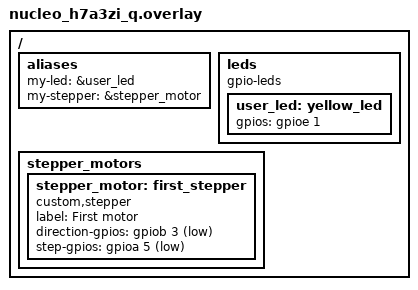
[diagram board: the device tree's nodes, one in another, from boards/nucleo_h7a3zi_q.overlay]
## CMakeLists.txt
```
cmake_minimum_required(VERSION 3.20)
find_package(Zephyr REQUIRED HINTS $ENV{ZEPHYR_BASE})
project(rmrc)
target_sources(app PRIVATE src/main.c src/motor.c)
target_include_directories(app PUBLIC ${CMAKE_CURRENT_SOURCE_DIR}/lib)
```

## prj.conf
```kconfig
CONFIG_GPIO=y
CONFIG_CONSOLE_SUBSYS=y
CONFIG_CONSOLE_GETLINE=y
CONFIG_UART_LINE_CTRL=y
CONFIG_UART_INTERRUPT_DRIVEN=y
CONFIG_PRINTK=y
CONFIG_SERIAL=y
CONFIG_CONSOLE=y
CONFIG_UART_CONSOLE=y
```

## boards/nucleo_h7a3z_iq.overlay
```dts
/{
   aliases {
     my-led=&yellow_led;
   };
   leds : leds {
  	compatible="gpio-leds";
  	yellow_led: e1 {
  	  gpios=<&gpioe 1 GPIO_ACTIVE-HIGH>;
	};

   };


};
```

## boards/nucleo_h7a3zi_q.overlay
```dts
/ {
    aliases {
        my-led = &user_led;
        my-stepper = &stepper_motor;
    };

    leds {
        compatible = "gpio-leds";

        user_led: yellow_led {
           gpios = <&gpioe 1 GPIO_ACTIVE_HIGH>;
        };
    };
    stepper_motors {

        stepper_motor: first_stepper {
           compatible="custom,stepper";
           label="First motor";
           direction-gpios = <&gpiob 3 GPIO_ACTIVE_LOW>;
           step-gpios = <&gpioa 5 GPIO_ACTIVE_LOW>;
        };
      
    };

};
```

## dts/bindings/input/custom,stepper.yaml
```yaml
description : Custom stepper
compatible : "custom,stepper"
properties :
  label :
    type : string
    required : false
  direction-gpios :
    type : phandle-array
    required : true
  step-gpios :
    type : phandle-array
    required : true
```

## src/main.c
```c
#include <stdio.h>
#include <zephyr/sys/printk.h>
#include <zephyr/kernel.h>
#include <zephyr/drivers/gpio.h>
#include <zephyr/console/console.h>
#include "motor.h"
#define sleep_time_ms 3
#define CONTROL_STACK_SIZE 512
#define MOTOR_STACK_SIZE 512
char msgq_buffer[10*sizeof(uint8_t)];
static struct k_msgq my_msgq;

K_THREAD_STACK_DEFINE(control_stack,CONTROL_STACK_SIZE);
K_THREAD_STACK_DEFINE(motor_stack,MOTOR_STACK_SIZE);
static struct  k_thread control_thread;
static struct k_thread motor_thred;
//K_MUTEX_DEFINE(stepper_mutex);
uint8_t rotation;
static const struct gpio_dt_spec led=GPIO_DT_SPEC_GET(DT_ALIAS(my_led),gpios);
static const struct gpio_dt_spec dir_motor=GPIO_DT_SPEC_GET(DT_ALIAS(my_stepper),direction_gpios);
static const struct gpio_dt_spec step_motor=GPIO_DT_SPEC_GET(DT_ALIAS(my_stepper),step_gpios);
static const struct stepper_motor my_motor = {
  .direction=dir_motor,
  .step=step_motor
};
void control_thread_start(void *arg1,void *arg2 , void *arg3){
  uint8_t dir;
  while(1){
    char *line=console_getline();
    if(line[0]=='w'){
      dir=1;
    }else if(line[0]=='a'){
      dir=0;
    }else {
      continue;
    }
    k_msgq_put(&my_msgq,&dir,K_NO_WAIT);
    /*
    k_mutex_lock(&stepper_mutex,K_FOREVER);
    rotation=(uint8_t)dir;
    k_mutex_unlock(&stepper_mutex);
    printk("Direction of rotation is : %d\n",rotation);
    */
    k_msleep(10);
  }
}

void motor_thread_start(void *arg1 , void *arg2 , void *arg3){
  uint8_t pulse=0;
  uint8_t direction_rotation=0;
  while(1){
    /*
    k_mutex_lock(&stepper_mutex,K_FOREVER);
    direction_rotation=rotation;
    k_mutex_unlock(&stepper_mutex);
    */
    k_msgq_get(&my_msgq,&direction_rotation,K_FOREVER);
    printk("The direction of the motor is : %d\n",direction_rotation);
    for(int i=0;i<50;i++){
      pulse=step_motion(&my_motor,direction_rotation,pulse);
    };
    if((pulse & 0x03)==0){
      gpio_pin_set_dt(&led,1);
      k_msleep(3);
    }else {
      gpio_pin_set_dt(&led,0);
    }
    printk("Rotating the stepper motor to one step \n");
  }
}
int main() {
  int motor_dir;
  int motor_step;
  uint8_t status=0;
  int ret;
  console_getline_init();
  status=1;
  ret=gpio_pin_configure_dt(&led,GPIO_OUTPUT_ACTIVE);
  motor_dir=gpio_pin_configure_dt(&dir_motor,GPIO_OUTPUT_ACTIVE);
  motor_step=gpio_pin_configure_dt(&step_motor,GPIO_OUTPUT_ACTIVE);
  k_tid_t motor;
  k_tid_t control;
  k_msgq_init(&my_msgq,msgq_buffer,sizeof(uint8_t),10);
  motor=k_thread_create(&motor_thred,motor_stack,K_THREAD_STACK_SIZEOF(motor_stack),motor_thread_start,NULL,NULL,NULL,8,0,K_NO_WAIT);
  control=k_thread_create(&control_thread,control_stack,K_THREAD_STACK_SIZEOF(control_stack),control_thread_start,NULL,NULL,NULL,7,0,K_NO_WAIT);
  gpio_pin_set_dt(&led,1);
  gpio_pin_set_dt(&dir_motor,0);
  gpio_pin_set_dt(&step_motor,0);
  if(motor_dir <0){
    printk("Device stepper nto configured properly");
  }
  if (motor_step <0){
    printk("Device stepper not configured properly the pulse channel");
  }
  if(ret<0){
    printk("Device led not configured proeprly");
  }
  while(1){
    /*
    char *line=console_getline();
    printk("Enter the direction to move\n");
    scanf(" %c",&input);
    if(input=='w'){
      dir=1;
    }else if(input =='a'){
      dir=0;
    }else {
      printk("Invalid key presses \n");
      return 0;
    }
    */
    /*
    if(line[0]=='w'){
      dir=1;
    }else if(line[0]=='a'){
      dir=0;
    }else {
      printk("Invalid character \n");
      continue;
    }
    pos=step_motion(&my_motor,dir,pos);
    if((pos & 0x03) ==0){
      gpio_pin_set_dt(&led,1);
      printk("led is ON stepper moved one step forward or back");
    }else{
      gpio_pin_set_dt(&led,0);
      printk("led is OFF");
    }
    */
    /*
    if(status==1){
      status=0;
    }else if(status==0){
      status=1;
    }
    
    printk("Status of the led : %d\n",status);
    gpio_pin_set_dt(&led,status);
    */
    k_sleep(K_FOREVER);
  }



}
```

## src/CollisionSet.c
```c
/*
 * Sponsored License - for use in support of a program or activity
 * sponsored by MathWorks.  Not for government, commercial or other
 * non-sponsored organizational use.
 * File: CollisionSet.c
 *
 * MATLAB Coder version            : 25.2
 * C/C++ source code generated on  : 07-Mar-2026 20:10:01
 */

/* Include Files */
#include "CollisionSet.h"
#include "psudoinverse_function_data.h"
#include "psudoinverse_function_emxutil.h"
#include "psudoinverse_function_types.h"
#include "rt_nonfinite.h"

/* Function Definitions */
/*
 * Arguments    : d_robotics_manip_internal_Colli *obj
 *                double maxElements
 * Return Type  : d_robotics_manip_internal_Colli *
 */
d_robotics_manip_internal_Colli *
CollisionSet_CollisionSet(d_robotics_manip_internal_Colli *obj,
                          double maxElements)
{
  static const void *t0_GeometryInternal = NULL;
  c_robotics_manip_internal_Colli expl_temp;
  d_robotics_manip_internal_Colli *b_obj;
  double d;
  int b_i;
  int i;
  int i1;
  int size_tmp_idx_1;
  b_obj = obj;
  b_obj->Size = 0.0;
  b_obj->MaxElements = maxElements;
  size_tmp_idx_1 = (int)b_obj->MaxElements;
  i = b_obj->CollisionGeometries->size[0] * b_obj->CollisionGeometries->size[1];
  b_obj->CollisionGeometries->size[0] = 1;
  b_obj->CollisionGeometries->size[1] = size_tmp_idx_1;
  c_emxEnsureCapacity_robotics_ma(b_obj->CollisionGeometries, i);
  d = b_obj->MaxElements;
  size_tmp_idx_1 = (int)d;
  for (b_i = 0; b_i < size_tmp_idx_1; b_i++) {
    expl_temp.CollisionPrimitive = (void *)t0_GeometryInternal;
    for (i1 = 0; i1 < 16; i1++) {
      expl_temp.LocalPose[i1] = iv[i1];
    }
    for (i1 = 0; i1 < 16; i1++) {
      expl_temp.WorldPose[i1] = iv[i1];
    }
    expl_temp.MeshScale[0] = 1.0;
    expl_temp.MeshScale[1] = 1.0;
    expl_temp.MeshScale[2] = 1.0;
    expl_temp.ColorAlpha[0] = 0.46666666666666667;
    expl_temp.ColorAlpha[1] = 0.67450980392156867;
    expl_temp.ColorAlpha[2] = 0.18823529411764706;
    expl_temp.ColorAlpha[3] = 1.0;
    b_obj->CollisionGeometries->data[b_i] = expl_temp;
  }
  b_obj->matlabCodegenIsDeleted = false;
  return b_obj;
}

/*
 * File trailer for CollisionSet.c
 *
 * [EOF]
 */
```

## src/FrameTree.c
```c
/*
 * Sponsored License - for use in support of a program or activity
 * sponsored by MathWorks.  Not for government, commercial or other
 * non-sponsored organizational use.
 * File: FrameTree.c
 *
 * MATLAB Coder version            : 25.2
 * C/C++ source code generated on  : 07-Mar-2026 20:10:01
 */

/* Include Files */
#include "FrameTree.h"
#include "psudoinverse_function_data.h"
#include "psudoinverse_function_types.h"
#include "rt_nonfinite.h"
#include <string.h>

/* Function Definitions */
/*
 * Arguments    : const emxArray_uint8_T *obj_FrameNames
 *                double obj_NumFrames
 * Return Type  : double
 */
double FrameTree_getFrameIdx(const emxArray_uint8_T *obj_FrameNames,
                             double obj_NumFrames)
{
  double fidx;
  int b_i;
  int i;
  unsigned char u8Name[200];
  const unsigned char *obj_FrameNames_data;
  bool exitg1;
  obj_FrameNames_data = obj_FrameNames->data;
  fidx = -1.0;
  memset(&u8Name[0], 0, 200U * sizeof(unsigned char));
  for (i = 0; i < 9; i++) {
    u8Name[i] = uv[i];
  }
  b_i = 0;
  exitg1 = false;
  while ((!exitg1) && (b_i <= (int)obj_NumFrames - 1)) {
    int k;
    bool x[200];
    bool exitg2;
    bool y;
    for (i = 0; i < 200; i++) {
      x[i] =
          (obj_FrameNames_data[b_i + obj_FrameNames->size[0] * i] == u8Name[i]);
    }
    y = true;
    k = 0;
    exitg2 = false;
    while ((!exitg2) && (k < 200)) {
      if (!x[k]) {
        y = false;
        exitg2 = true;
      } else {
        k++;
      }
    }
    if (y) {
      fidx = (double)b_i + 1.0;
      exitg1 = true;
    } else {
      b_i++;
    }
  }
  return fidx;
}

/*
 * Arguments    : const emxArray_uint8_T *obj_FrameNames
 *                double obj_NumFrames
 *                double *fidx
 * Return Type  : bool
 */
bool FrameTree_isFrameInTree(const emxArray_uint8_T *obj_FrameNames,
                             double obj_NumFrames, double *fidx)
{
  static const unsigned char b_uv[6] = {108U, 105U, 110U, 107U, 95U, 49U};
  int b_i;
  int i;
  unsigned char u8Name[200];
  const unsigned char *obj_FrameNames_data;
  bool exitg1;
  bool tf;
  obj_FrameNames_data = obj_FrameNames->data;
  *fidx = -1.0;
  memset(&u8Name[0], 0, 200U * sizeof(unsigned char));
  for (i = 0; i < 6; i++) {
    u8Name[i] = b_uv[i];
  }
  b_i = 0;
  exitg1 = false;
  while ((!exitg1) && (b_i <= (int)obj_NumFrames - 1)) {
    int k;
    bool x[200];
    bool exitg2;
    for (i = 0; i < 200; i++) {
      x[i] =
          (obj_FrameNames_data[b_i + obj_FrameNames->size[0] * i] == u8Name[i]);
    }
    tf = true;
    k = 0;
    exitg2 = false;
    while ((!exitg2) && (k < 200)) {
      if (!x[k]) {
        tf = false;
        exitg2 = true;
      } else {
        k++;
      }
    }
    if (tf) {
      *fidx = (double)b_i + 1.0;
      exitg1 = true;
    } else {
      b_i++;
    }
  }
  return *fidx > 0.0;
}

/*
 * Arguments    : const emxArray_real_T *obj_FrameParents
 *                const emxArray_real_T *obj_FrameRigidTransforms
 *                double fid1
 *                double tform[16]
 * Return Type  : void
 */
void FrameTree_transformUsingFrameID(
    const emxArray_real_T *obj_FrameParents,
    const emxArray_real_T *obj_FrameRigidTransforms, double fid1,
    double tform[16])
{
  double T1[16];
  double b_R[16];
  double d_R[3];
  const double *obj_FrameParents_data;
  const double *obj_FrameRigidTransforms_data;
  int i;
  int i1;
  obj_FrameRigidTransforms_data = obj_FrameRigidTransforms->data;
  obj_FrameParents_data = obj_FrameParents->data;
  if (fid1 == 1.0) {
    memset(&tform[0], 0, 16U * sizeof(double));
    tform[0] = 1.0;
    tform[5] = 1.0;
    tform[10] = 1.0;
    tform[15] = 1.0;
  } else {
    double R[9];
    double c_R[9];
    double d;
    double d1;
    double fid;
    int T1_tmp;
    int b_T1_tmp;
    fid = fid1;
    for (i = 0; i < 4; i++) {
      T1_tmp = i << 2;
      b_T1_tmp = 4 * i + 16 * ((int)fid1 - 1);
      T1[T1_tmp] = obj_FrameRigidTransforms_data[b_T1_tmp];
      T1[T1_tmp + 1] = obj_FrameRigidTransforms_data[b_T1_tmp + 1];
      T1[T1_tmp + 2] = obj_FrameRigidTransforms_data[b_T1_tmp + 2];
      T1[T1_tmp + 3] = obj_FrameRigidTransforms_data[b_T1_tmp + 3];
    }
    while (fid > 1.0) {
      memset(&b_R[0], 0, sizeof(double) << 4);
      for (i = 0; i < 4; i++) {
        b_T1_tmp = i << 2;
        for (i1 = 0; i1 < 4; i1++) {
          d = T1[i1 + b_T1_tmp];
          T1_tmp = (int)obj_FrameParents_data[(int)fid - 1] - 1;
          T1_tmp = 4 * i1 + 16 * T1_tmp;
          b_R[b_T1_tmp] += obj_FrameRigidTransforms_data[T1_tmp] * d;
          b_R[b_T1_tmp + 1] += obj_FrameRigidTransforms_data[T1_tmp + 1] * d;
          b_R[b_T1_tmp + 2] += obj_FrameRigidTransforms_data[T1_tmp + 2] * d;
          b_R[b_T1_tmp + 3] += obj_FrameRigidTransforms_data[T1_tmp + 3] * d;
        }
      }
      memcpy(&T1[0], &b_R[0], 16U * sizeof(double));
      fid = obj_FrameParents_data[(int)fid - 1];
    }
    for (i = 0; i < 3; i++) {
      R[3 * i] = obj_FrameRigidTransforms_data[i];
      R[3 * i + 1] = obj_FrameRigidTransforms_data[i + 4];
      R[3 * i + 2] = obj_FrameRigidTransforms_data[i + 8];
    }
    for (i = 0; i < 9; i++) {
      c_R[i] = -R[i];
    }
    memset(&d_R[0], 0, 3U * sizeof(double));
    fid = d_R[0];
    d = d_R[1];
    d1 = d_R[2];
    for (i = 0; i < 3; i++) {
      double d2;
      d2 = obj_FrameRigidTransforms_data[i + 12];
      fid += c_R[3 * i] * d2;
      b_T1_tmp = i << 2;
      b_R[b_T1_tmp] = R[3 * i];
      T1_tmp = 3 * i + 1;
      d += c_R[T1_tmp] * d2;
      b_R[b_T1_tmp + 1] = R[T1_tmp];
      T1_tmp = 3 * i + 2;
      d1 += c_R[T1_tmp] * d2;
      b_R[b_T1_tmp + 2] = R[T1_tmp];
    }
    b_R[12] = fid;
    b_R[13] = d;
    b_R[14] = d1;
    b_R[3] = 0.0;
    b_R[7] = 0.0;
    b_R[11] = 0.0;
    b_R[15] = 1.0;
    memset(&tform[0], 0, sizeof(double) << 4);
    for (i = 0; i < 4; i++) {
      T1_tmp = i << 2;
      for (i1 = 0; i1 < 4; i1++) {
        fid = T1[i1 + T1_tmp];
        b_T1_tmp = i1 << 2;
        tform[T1_tmp] += b_R[b_T1_tmp] * fid;
        tform[T1_tmp + 1] += b_R[b_T1_tmp + 1] * fid;
        tform[T1_tmp + 2] += b_R[b_T1_tmp + 2] * fid;
        tform[T1_tmp + 3] += b_R[b_T1_tmp + 3] * fid;
      }
    }
  }
}

/*
 * Arguments    : const emxArray_uint8_T *obj_FrameNames
 *                double obj_NumFrames
 *                double *fidx
 * Return Type  : bool
 */
bool b_FrameTree_isFrameInTree(const emxArray_uint8_T *obj_FrameNames,
                               double obj_NumFrames, double *fidx)
{
  static const unsigned char b_uv[6] = {108U, 105U, 110U, 107U, 95U, 50U};
  int b_i;
  int i;
  unsigned char u8Name[200];
  const unsigned char *obj_FrameNames_data;
  bool exitg1;
  bool tf;
  obj_FrameNames_data = obj_FrameNames->data;
  *fidx = -1.0;
  memset(&u8Name[0], 0, 200U * sizeof(unsigned char));
  for (i = 0; i < 6; i++) {
    u8Name[i] = b_uv[i];
  }
  b_i = 0;
  exitg1 = false;
  while ((!exitg1) && (b_i <= (int)obj_NumFrames - 1)) {
    int k;
    bool x[200];
    bool exitg2;
    for (i = 0; i < 200; i++) {
      x[i] =
          (obj_FrameNames_data[b_i + obj_FrameNames->size[0] * i] == u8Name[i]);
    }
    tf = true;
    k = 0;
    exitg2 = false;
    while ((!exitg2) && (k < 200)) {
      if (!x[k]) {
        tf = false;
        exitg2 = true;
      } else {
        k++;
      }
    }
    if (tf) {
      *fidx = (double)b_i + 1.0;
      exitg1 = true;
    } else {
      b_i++;
    }
  }
  return *fidx > 0.0;
}

/*
 * Arguments    : const emxArray_uint8_T *obj_FrameNames
 *                double obj_NumFrames
 *                double *fidx
 * Return Type  : bool
 */
bool c_FrameTree_isFrameInTree(const emxArray_uint8_T *obj_FrameNames,
                               double obj_NumFrames, double *fidx)
{
  static const unsigned char b_uv[6] = {108U, 105U, 110U, 107U, 95U, 51U};
  int b_i;
  int i;
  unsigned char u8Name[200];
  const unsigned char *obj_FrameNames_data;
  bool exitg1;
  bool tf;
  obj_FrameNames_data = obj_FrameNames->data;
  *fidx = -1.0;
  memset(&u8Name[0], 0, 200U * sizeof(unsigned char));
  for (i = 0; i < 6; i++) {
    u8Name[i] = b_uv[i];
  }
  b_i = 0;
  exitg1 = false;
  while ((!exitg1) && (b_i <= (int)obj_NumFrames - 1)) {
    int k;
    bool x[200];
    bool exitg2;
    for (i = 0; i < 200; i++) {
      x[i] =
          (obj_FrameNames_data[b_i + obj_FrameNames->size[0] * i] == u8Name[i]);
    }
    tf = true;
    k = 0;
    exitg2 = false;
    while ((!exitg2) && (k < 200)) {
      if (!x[k]) {
        tf = false;
        exitg2 = true;
      } else {
        k++;
      }
    }
    if (tf) {
      *fidx = (double)b_i + 1.0;
      exitg1 = true;
    } else {
      b_i++;
    }
  }
  return *fidx > 0.0;
}

/*
 * Arguments    : const emxArray_uint8_T *obj_FrameNames
 *                double obj_NumFrames
 *                double *fidx
 * Return Type  : bool
 */
bool d_FrameTree_isFrameInTree(const emxArray_uint8_T *obj_FrameNames,
                               double obj_NumFrames, double *fidx)
{
  static const unsigned char b_uv[6] = {108U, 105U, 110U, 107U, 95U, 52U};
  int b_i;
  int i;
  unsigned char u8Name[200];
  const unsigned char *obj_FrameNames_data;
  bool exitg1;
  bool tf;
  obj_FrameNames_data = obj_FrameNames->data;
  *fidx = -1.0;
  memset(&u8Name[0], 0, 200U * sizeof(unsigned char));
  for (i = 0; i < 6; i++) {
    u8Name[i] = b_uv[i];
  }
  b_i = 0;
  exitg1 = false;
  while ((!exitg1) && (b_i <= (int)obj_NumFrames - 1)) {
    int k;
    bool x[200];
    bool exitg2;
    for (i = 0; i < 200; i++) {
      x[i] =
          (obj_FrameNames_data[b_i + obj_FrameNames->size[0] * i] == u8Name[i]);
    }
    tf = true;
    k = 0;
    exitg2 = false;
    while ((!exitg2) && (k < 200)) {
      if (!x[k]) {
        tf = false;
        exitg2 = true;
      } else {
        k++;
      }
    }
    if (tf) {
      *fidx = (double)b_i + 1.0;
      exitg1 = true;
    } else {
      b_i++;
    }
  }
  return *fidx > 0.0;
}

/*
 * Arguments    : const emxArray_uint8_T *obj_FrameNames
 *                double obj_NumFrames
 *                double *fidx
 * Return Type  : bool
 */
bool e_FrameTree_isFrameInTree(const emxArray_uint8_T *obj_FrameNames,
                               double obj_NumFrames, double *fidx)
{
  static const unsigned char b_uv[6] = {108U, 105U, 110U, 107U, 95U, 53U};
  int b_i;
  int i;
  unsigned char u8Name[200];
  const unsigned char *obj_FrameNames_data;
  bool exitg1;
  bool tf;
  obj_FrameNames_data = obj_FrameNames->data;
  *fidx = -1.0;
  memset(&u8Name[0], 0, 200U * sizeof(unsigned char));
  for (i = 0; i < 6; i++) {
    u8Name[i] = b_uv[i];
  }
  b_i = 0;
  exitg1 = false;
  while ((!exitg1) && (b_i <= (int)obj_NumFrames - 1)) {
    int k;
    bool x[200];
    bool exitg2;
    for (i = 0; i < 200; i++) {
      x[i] =
          (obj_FrameNames_data[b_i + obj_FrameNames->size[0] * i] == u8Name[i]);
    }
    tf = true;
    k = 0;
    exitg2 = false;
    while ((!exitg2) && (k < 200)) {
      if (!x[k]) {
        tf = false;
        exitg2 = true;
      } else {
        k++;
      }
    }
    if (tf) {
      *fidx = (double)b_i + 1.0;
      exitg1 = true;
    } else {
      b_i++;
    }
  }
  return *fidx > 0.0;
}

/*
 * Arguments    : const emxArray_uint8_T *obj_FrameNames
 *                double obj_NumFrames
 *                double *fidx
 * Return Type  : bool
 */
bool f_FrameTree_isFrameInTree(const emxArray_uint8_T *obj_FrameNames,
                               double obj_NumFrames, double *fidx)
{
  static const unsigned char b_uv[6] = {108U, 105U, 110U, 107U, 95U, 54U};
  int b_i;
  int i;
  unsigned char u8Name[200];
  const unsigned char *obj_FrameNames_data;
  bool exitg1;
  bool tf;
  obj_FrameNames_data = obj_FrameNames->data;
  *fidx = -1.0;
  memset(&u8Name[0], 0, 200U * sizeof(unsigned char));
  for (i = 0; i < 6; i++) {
    u8Name[i] = b_uv[i];
  }
  b_i = 0;
  exitg1 = false;
  while ((!exitg1) && (b_i <= (int)obj_NumFrames - 1)) {
    int k;
    bool x[200];
    bool exitg2;
    for (i = 0; i < 200; i++) {
      x[i] =
          (obj_FrameNames_data[b_i + obj_FrameNames->size[0] * i] == u8Name[i]);
    }
    tf = true;
    k = 0;
    exitg2 = false;
    while ((!exitg2) && (k < 200)) {
      if (!x[k]) {
        tf = false;
        exitg2 = true;
      } else {
        k++;
      }
    }
    if (tf) {
      *fidx = (double)b_i + 1.0;
      exitg1 = true;
    } else {
      b_i++;
    }
  }
  return *fidx > 0.0;
}

/*
 * Arguments    : const emxArray_uint8_T *obj_FrameNames
 *                double obj_NumFrames
 *                const char name[5]
 *                double *fidx
 * Return Type  : bool
 */
bool g_FrameTree_isFrameInTree(const emxArray_uint8_T *obj_FrameNames,
                               double obj_NumFrames, const char name[5],
                               double *fidx)
{
  int b_i;
  int i;
  unsigned char u8Name[200];
  const unsigned char *obj_FrameNames_data;
  bool exitg1;
  bool tf;
  obj_FrameNames_data = obj_FrameNames->data;
  *fidx = -1.0;
  memset(&u8Name[0], 0, 200U * sizeof(unsigned char));
  for (i = 0; i < 5; i++) {
    u8Name[i] = (unsigned char)name[i];
  }
  b_i = 0;
  exitg1 = false;
  while ((!exitg1) && (b_i <= (int)obj_NumFrames - 1)) {
    int k;
    bool x[200];
    bool exitg2;
    for (i = 0; i < 200; i++) {
      x[i] =
          (obj_FrameNames_data[b_i + obj_FrameNames->size[0] * i] == u8Name[i]);
    }
    tf = true;
    k = 0;
    exitg2 = false;
    while ((!exitg2) && (k < 200)) {
      if (!x[k]) {
        tf = false;
        exitg2 = true;
      } else {
        k++;
      }
    }
    if (tf) {
      *fidx = (double)b_i + 1.0;
      exitg1 = true;
    } else {
      b_i++;
    }
  }
  return *fidx > 0.0;
}

/*
 * File trailer for FrameTree.c
 *
 * [EOF]
 */
```

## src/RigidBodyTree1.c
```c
/*
 * Sponsored License - for use in support of a program or activity
 * sponsored by MathWorks.  Not for government, commercial or other
 * non-sponsored organizational use.
 * File: RigidBodyTree1.c
 *
 * MATLAB Coder version            : 25.2
 * C/C++ source code generated on  : 07-Mar-2026 20:10:01
 */

/* Include Files */
#include "RigidBodyTree1.h"
#include "CollisionSet.h"
#include "FrameTree.h"
#include "psudoinverse_function_data.h"
#include "psudoinverse_function_emxutil.h"
#include "psudoinverse_function_internal_types.h"
#include "psudoinverse_function_types.h"
#include "rand.h"
#include "rigidBodyJoint.h"
#include "rt_nonfinite.h"
#include "strcmp.h"
#include <math.h>
#include <string.h>

/* Function Definitions */
/*
 * Arguments    : e_robotics_manip_internal_Rigid *obj
 * Return Type  : e_robotics_manip_internal_Rigid *
 */
e_robotics_manip_internal_Rigid *
RigidBodyTree_RigidBodyTree(e_robotics_manip_internal_Rigid *obj)
{
  static const char jname[14] = {'d', 'u', 'm', 'm', 'y', 'b', 'o',
                                 'd', 'y', '1', '_', 'j', 'n', 't'};
  c_robotics_manip_internal_Chara s;
  e_robotics_manip_internal_Rigid *b_obj;
  double unusedExpr[5];
  int i;
  b_obj = obj;
  b_rand(unusedExpr);
  s.Length = 200.0;
  for (i = 0; i < 200; i++) {
    s.Vector[i] = ' ';
  }
  b_obj->Base.NameInternal = s;
  s = b_obj->Base.NameInternal;
  s.Length = 4.0;
  s.Vector[0] = 'b';
  s.Vector[1] = 'a';
  s.Vector[2] = 's';
  s.Vector[3] = 'e';
  b_obj->Base.NameInternal = s;
  rigidBodyJoint_rigidBodyJoint(&b_obj->Base.JointInternal);
  b_obj->Base.JointInternal.InTree = false;
  CollisionSet_CollisionSet(&b_obj->Base.CollisionsInternal, 0.0);
  b_obj->Base.matlabCodegenIsDeleted = false;
  s.Length = 200.0;
  for (i = 0; i < 200; i++) {
    s.Vector[i] = ' ';
  }
  b_obj->coder_buffer_pobj0.NameInternal = s;
  s = b_obj->coder_buffer_pobj0.NameInternal;
  s.Length = 10.0;
  for (i = 0; i < 10; i++) {
    s.Vector[i] = cv[i];
  }
  b_obj->coder_buffer_pobj0.NameInternal = s;
  b_rigidBodyJoint_rigidBodyJoint(&b_obj->coder_buffer_pobj0.JointInternal,
                                  jname);
  b_obj->coder_buffer_pobj0.JointInternal.InTree = false;
  CollisionSet_CollisionSet(&b_obj->coder_buffer_pobj0.CollisionsInternal, 0.0);
  b_obj->coder_buffer_pobj0.matlabCodegenIsDeleted = false;
  b_obj->Bodies[0] = &b_obj->coder_buffer_pobj0;
  b_rand(unusedExpr);
  b_obj->matlabCodegenIsDeleted = false;
  return b_obj;
}

/*
 * Arguments    : f_robotics_manip_internal_Rigid *obj
 *                const double qvec[6]
 *                cell_wrap_30 Ttree_data[]
 *                int Ttree_size[2]
 * Return Type  : void
 */
void RigidBodyTree_forwardKinematics(f_robotics_manip_internal_Rigid *obj,
                                     const double qvec[6],
                                     cell_wrap_30 Ttree_data[],
                                     int Ttree_size[2])
{
  static const char b_cv[8] = {'r', 'e', 'v', 'o', 'l', 'u', 't', 'e'};
  static const char b_cv1[8] = {'f', 'l', 'o', 'a', 't', 'i', 'n', 'g'};
  c_robotics_manip_internal_Frame expl_temp;
  c_robotics_manip_internal_Rigid *body;
  rigidBodyJoint *b_obj;
  double b[16];
  double b_I[16];
  double b_a[16];
  double b_b[16];
  double tempR[9];
  double k;
  double n;
  double result_data_idx_3;
  int b_i;
  int i;
  int i1;
  int jtilecol;
  n = obj->NumBodies;
  Ttree_size[0] = 1;
  i = (int)n;
  Ttree_size[1] = (int)n;
  if ((int)n != 0) {
    for (jtilecol = 0; jtilecol < i; jtilecol++) {
      for (i1 = 0; i1 < 16; i1++) {
        Ttree_data[jtilecol].f1[i1] = iv[i1];
      }
    }
  }
  k = 1.0;
  e_emxInitStruct_robotics_manip_(&expl_temp);
  for (b_i = 0; b_i < i; b_i++) {
    double a[16];
    double d;
    int a_tmp;
    int b_index;
    int b_tmp;
    int exitg1;
    int i2;
    char obj_Vector[200];
    bool result;
    body = obj->Bodies[b_i];
    n = body->JointInternal->PositionNumber;
    d = k + n;
    if (k > d - 1.0) {
      i2 = -1;
      a_tmp = 0;
    } else {
      i2 = (int)k - 2;
      a_tmp = (int)(d - 1.0);
    }
    n = obj->BodyParentFrameIdx[b_i];
    if (obj->Bodies[b_i]->ParentIndex > 0.0) {
      c_emxCopyStruct_robotics_manip_(
          &expl_temp,
          &obj->Bodies[(int)obj->Bodies[b_i]->ParentIndex - 1]->FramesInternal);
      FrameTree_transformUsingFrameID(expl_temp.FrameParents,
                                      expl_temp.FrameRigidTransforms, n, a);
    } else {
      FrameTree_transformUsingFrameID(
          obj->Base.FramesInternal.FrameParents,
          obj->Base.FramesInternal.FrameRigidTransforms, n, a);
    }
    b_obj = body->JointInternal;
    for (jtilecol = 0; jtilecol < 16; jtilecol++) {
      b_a[jtilecol] = b_obj->JointToParentTransform[jtilecol];
    }
    n = b_obj->TypeInternal.Length;
    for (jtilecol = 0; jtilecol < 200; jtilecol++) {
      obj_Vector[jtilecol] = b_obj->TypeInternal.Vector[jtilecol];
    }
    if (n < 1.0) {
      b_tmp = 0;
    } else {
      b_tmp = (int)n;
    }
    result = false;
    if (b_tmp == 8) {
      b_index = 0;
      do {
        exitg1 = 0;
        if (b_index < 8) {
          if (b_cv[b_index] != obj_Vector[b_index]) {
            exitg1 = 1;
          } else {
            b_index++;
          }
        } else {
          result = true;
          exitg1 = 1;
        }
      } while (exitg1 == 0);
    }
    if (result) {
      b_index = 0;
    } else {
      result = false;
      if (b_tmp == 9) {
        b_index = 0;
        do {
          exitg1 = 0;
          if (b_index < 9) {
            if (cv1[b_index] != obj_Vector[b_index]) {
              exitg1 = 1;
            } else {
              b_index++;
            }
          } else {
            result = true;
            exitg1 = 1;
          }
        } while (exitg1 == 0);
      }
      if (result) {
        b_index = 1;
      } else {
        result = false;
        if (b_tmp == 8) {
          b_index = 0;
          do {
            exitg1 = 0;
            if (b_index < 8) {
              if (b_cv1[b_index] != obj_Vector[b_index]) {
                exitg1 = 1;
              } else {
                b_index++;
              }
            } else {
              result = true;
              exitg1 = 1;
            }
          } while (exitg1 == 0);
        }
        if (result) {
          b_index = 2;
        } else {
          b_index = -1;
        }
      }
    }
    switch (b_index) {
    case 0: {
      double R[9];
      double v[3];
      double sth;
      rigidBodyJoint_get_JointAxis(b_obj, v);
      n = v[0];
      k = v[1];
      sth = v[2];
      b_index = ((a_tmp - i2) - 1 != 0);
      for (jtilecol = 0; jtilecol < b_index; jtilecol++) {
        result_data_idx_3 = qvec[i2 + 1];
      }
      double c_b;
      double cth;
      double d_tempR_tmp;
      double f_tempR_tmp;
      double g_tempR_tmp;
      double normRowMatrix_idx_1;
      double normRowMatrix_tmp;
      double tempR_tmp;
      normRowMatrix_tmp = 1.0 / sqrt((n * n + k * k) + sth * sth);
      v[0] = n * normRowMatrix_tmp;
      v[1] = k * normRowMatrix_tmp;
      v[2] = sth * normRowMatrix_tmp;
      cth = cos(result_data_idx_3);
      sth = sin(result_data_idx_3);
      tempR_tmp = v[0] * v[0] * (1.0 - cth) + cth;
      tempR[0] = tempR_tmp;
      n = v[0] * v[1] * (1.0 - cth);
      k = v[2] * sth;
      normRowMatrix_idx_1 = n - k;
      tempR[1] = normRowMatrix_idx_1;
      normRowMatrix_tmp = v[0] * v[2] * (1.0 - cth);
      c_b = v[1] * sth;
      d_tempR_tmp = normRowMatrix_tmp + c_b;
      tempR[2] = d_tempR_tmp;
      f_tempR_tmp = n + k;
      tempR[3] = f_tempR_tmp;
      g_tempR_tmp = v[1] * v[1] * (1.0 - cth) + cth;
      tempR[4] = g_tempR_tmp;
      k = v[1] * v[2] * (1.0 - cth);
      n = v[0] * sth;
      sth = k - n;
      tempR[5] = sth;
      normRowMatrix_tmp -= c_b;
      tempR[6] = normRowMatrix_tmp;
      k += n;
      tempR[7] = k;
      n = v[2] * v[2] * (1.0 - cth) + cth;
      tempR[8] = n;
      R[0] = tempR_tmp;
      R[1] = normRowMatrix_idx_1;
      R[2] = d_tempR_tmp;
      R[3] = f_tempR_tmp;
      R[4] = g_tempR_tmp;
      R[5] = sth;
      R[6] = normRowMatrix_tmp;
      R[7] = k;
      R[8] = n;
      for (jtilecol = 0; jtilecol < 3; jtilecol++) {
        R[jtilecol] = tempR[3 * jtilecol];
        R[jtilecol + 3] = tempR[3 * jtilecol + 1];
        R[jtilecol + 6] = tempR[3 * jtilecol + 2];
      }
      memset(&b[0], 0, 16U * sizeof(double));
      for (jtilecol = 0; jtilecol < 3; jtilecol++) {
        b_index = jtilecol << 2;
        b[b_index] = R[3 * jtilecol];
        b[b_index + 1] = R[3 * jtilecol + 1];
        b[b_index + 2] = R[3 * jtilecol + 2];
      }
      b[15] = 1.0;
    } break;
    case 1: {
      double v[3];
      rigidBodyJoint_get_JointAxis(b_obj, v);
      memset(&tempR[0], 0, 9U * sizeof(double));
      tempR[0] = 1.0;
      tempR[4] = 1.0;
      tempR[8] = 1.0;
      for (jtilecol = 0; jtilecol < 3; jtilecol++) {
        b_index = jtilecol << 2;
        b[b_index] = tempR[3 * jtilecol];
        b[b_index + 1] = tempR[3 * jtilecol + 1];
        b[b_index + 2] = tempR[3 * jtilecol + 2];
        b[jtilecol + 12] = v[jtilecol] * qvec[i2 + 1];
      }
      b[3] = 0.0;
      b[7] = 0.0;
      b[11] = 0.0;
      b[15] = 1.0;
    } break;
    case 2: {
      double R[9];
      double b_tempR_tmp;
      double c_b;
      double c_tempR_tmp;
      double cth;
      double d_tempR_tmp;
      double e_tempR_tmp;
      double f_tempR_tmp;
      double g_tempR_tmp;
      double h_tempR_tmp;
      double normRowMatrix_idx_0;
      double normRowMatrix_idx_1;
      double normRowMatrix_tmp;
      double sth;
      double tempR_tmp;
      memset(&b_I[0], 0, 16U * sizeof(double));
      b_I[0] = 1.0;
      b_I[5] = 1.0;
      b_I[10] = 1.0;
      b_I[15] = 1.0;
      b_I[12] = qvec[i2 + 5];
      b_I[13] = qvec[i2 + 6];
      b_I[14] = qvec[i2 + 7];
      n = qvec[i2 + 1];
      k = qvec[i2 + 2];
      sth = qvec[i2 + 3];
      normRowMatrix_tmp = qvec[i2 + 4];
      c_b = 1.0 / sqrt(((n * n + k * k) + sth * sth) +
                       normRowMatrix_tmp * normRowMatrix_tmp);
      normRowMatrix_idx_0 = n * c_b;
      normRowMatrix_idx_1 = k * c_b;
      sth *= c_b;
      c_b *= normRowMatrix_tmp;
      normRowMatrix_tmp = c_b * c_b;
      b_tempR_tmp = sth * sth;
      c_tempR_tmp = 1.0 - 2.0 * (b_tempR_tmp + normRowMatrix_tmp);
      tempR[0] = c_tempR_tmp;
      n = normRowMatrix_idx_1 * sth;
      k = normRowMatrix_idx_0 * c_b;
      e_tempR_tmp = 2.0 * (n - k);
      tempR[1] = e_tempR_tmp;
      f_tempR_tmp = normRowMatrix_idx_1 * c_b;
      g_tempR_tmp = normRowMatrix_idx_0 * sth;
      h_tempR_tmp = 2.0 * (f_tempR_tmp + g_tempR_tmp);
      tempR[2] = h_tempR_tmp;
      d_tempR_tmp = 2.0 * (n + k);
      tempR[3] = d_tempR_tmp;
      cth = normRowMatrix_idx_1 * normRowMatrix_idx_1;
      tempR_tmp = 1.0 - 2.0 * (cth + normRowMatrix_tmp);
      tempR[4] = tempR_tmp;
      k = sth * c_b;
      n = normRowMatrix_idx_0 * normRowMatrix_idx_1;
      c_b = 2.0 * (k - n);
      tempR[5] = c_b;
      normRowMatrix_tmp = 2.0 * (f_tempR_tmp - g_tempR_tmp);
      tempR[6] = normRowMatrix_tmp;
      k = 2.0 * (k + n);
      tempR[7] = k;
      n = 1.0 - 2.0 * (cth + b_tempR_tmp);
      tempR[8] = n;
      R[0] = c_tempR_tmp;
      R[1] = e_tempR_tmp;
      R[2] = h_tempR_tmp;
      R[3] = d_tempR_tmp;
      R[4] = tempR_tmp;
      R[5] = c_b;
      R[6] = normRowMatrix_tmp;
      R[7] = k;
      R[8] = n;
      for (jtilecol = 0; jtilecol < 3; jtilecol++) {
        R[jtilecol] = tempR[3 * jtilecol];
        R[jtilecol + 3] = tempR[3 * jtilecol + 1];
        R[jtilecol + 6] = tempR[3 * jtilecol + 2];
      }
      memset(&b_b[0], 0, 16U * sizeof(double));
      for (jtilecol = 0; jtilecol < 3; jtilecol++) {
        b_index = jtilecol << 2;
        b_b[b_index] = R[3 * jtilecol];
        b_b[b_index + 1] = R[3 * jtilecol + 1];
        b_b[b_index + 2] = R[3 * jtilecol + 2];
      }
      b_b[15] = 1.0;
      memset(&b[0], 0, sizeof(double) << 4);
      for (jtilecol = 0; jtilecol < 4; jtilecol++) {
        b_index = jtilecol << 2;
        for (i1 = 0; i1 < 4; i1++) {
          n = b_b[i1 + b_index];
          b_tmp = i1 << 2;
          b[b_index] += b_I[b_tmp] * n;
          b[b_index + 1] += b_I[b_tmp + 1] * n;
          b[b_index + 2] += b_I[b_tmp + 2] * n;
          b[b_index + 3] += b_I[b_tmp + 3] * n;
        }
      }
    } break;
    default:
      memset(&b[0], 0, 16U * sizeof(double));
      b[0] = 1.0;
      b[5] = 1.0;
      b[10] = 1.0;
      b[15] = 1.0;
      break;
    }
    for (jtilecol = 0; jtilecol < 16; jtilecol++) {
      b_b[jtilecol] = b_obj->ChildToJointTransform[jtilecol];
    }
    memset(&b_I[0], 0, sizeof(double) << 4);
    for (jtilecol = 0; jtilecol < 4; jtilecol++) {
      b_index = jtilecol << 2;
      for (i1 = 0; i1 < 4; i1++) {
        n = b[i1 + b_index];
        b_tmp = i1 << 2;
        b_I[b_index] += b_a[b_tmp] * n;
        b_I[b_index + 1] += b_a[b_tmp + 1] * n;
        b_I[b_index + 2] += b_a[b_tmp + 2] * n;
        b_I[b_index + 3] += b_a[b_tmp + 3] * n;
      }
    }
    memset(&b_a[0], 0, sizeof(double) << 4);
    for (i1 = 0; i1 < 4; i1++) {
      b_index = i1 << 2;
      for (jtilecol = 0; jtilecol < 4; jtilecol++) {
        b_tmp = jtilecol + b_index;
        n = b_b[b_tmp];
        a_tmp = jtilecol << 2;
        b_a[b_index] += b_I[a_tmp] * n;
        b_a[b_index + 1] += b_I[a_tmp + 1] * n;
        b_a[b_index + 2] += b_I[a_tmp + 2] * n;
        b_a[b_index + 3] += b_I[a_tmp + 3] * n;
        Ttree_data[b_i].f1[b_tmp] = 0.0;
      }
      b_index = i1 << 2;
      for (jtilecol = 0; jtilecol < 4; jtilecol++) {
        n = b_a[jtilecol + b_index];
        b_tmp = jtilecol << 2;
        Ttree_data[b_i].f1[b_index] += a[b_tmp] * n;
        Ttree_data[b_i].f1[b_index + 1] += a[b_tmp + 1] * n;
        Ttree_data[b_i].f1[b_index + 2] += a[b_tmp + 2] * n;
        Ttree_data[b_i].f1[b_index + 3] += a[b_tmp + 3] * n;
      }
    }
    k = d;
    if (body->ParentIndex > 0.0) {
      for (jtilecol = 0; jtilecol < 16; jtilecol++) {
        a[jtilecol] = Ttree_data[(int)body->ParentIndex - 1].f1[jtilecol];
      }
      memset(&b_a[0], 0, sizeof(double) << 4);
      for (jtilecol = 0; jtilecol < 4; jtilecol++) {
        b_index = jtilecol << 2;
        for (i1 = 0; i1 < 4; i1++) {
          n = Ttree_data[b_i].f1[i1 + b_index];
          b_tmp = i1 << 2;
          b_a[b_index] += a[b_tmp] * n;
          b_a[b_index + 1] += a[b_tmp + 1] * n;
          b_a[b_index + 2] += a[b_tmp + 2] * n;
          b_a[b_index + 3] += a[b_tmp + 3] * n;
        }
      }
      memcpy(&Ttree_data[b_i].f1[0], &b_a[0], 16U * sizeof(double));
    }
  }
  c_emxFreeStruct_robotics_manip_(&expl_temp);
}

/*
 * Arguments    : f_robotics_manip_internal_Rigid *obj
 * Return Type  : double
 */
double c_RigidBodyTree_findBodyIndexBy(f_robotics_manip_internal_Rigid *obj)
{
  c_robotics_manip_internal_Rigid *b_obj;
  double bid;
  double obj_Length;
  int exitg1;
  int i;
  int kstr;
  char obj_Vector[200];
  bool b_bool;
  bid = -1.0;
  obj_Length = obj->Base.NameInternal.Length;
  for (i = 0; i < 200; i++) {
    obj_Vector[i] = obj->Base.NameInternal.Vector[i];
  }
  if (obj_Length < 1.0) {
    kstr = 0;
  } else {
    kstr = (int)obj_Length;
  }
  b_bool = false;
  if (kstr == 9) {
    kstr = 0;
    do {
      exitg1 = 0;
      if (kstr < 9) {
        if (obj_Vector[kstr] != cv2[kstr]) {
          exitg1 = 1;
        } else {
          kstr++;
        }
      } else {
        b_bool = true;
        exitg1 = 1;
      }
    } while (exitg1 == 0);
  }
  if (b_bool) {
    bid = 0.0;
  } else {
    double d;
    int b_i;
    bool exitg2;
    d = obj->NumBodies;
    b_i = 0;
    exitg2 = false;
    while ((!exitg2) && (b_i <= (int)d - 1)) {
      b_obj = obj->Bodies[b_i];
      obj_Length = b_obj->NameInternal.Length;
      for (i = 0; i < 200; i++) {
        obj_Vector[i] = b_obj->NameInternal.Vector[i];
      }
      if (obj_Length < 1.0) {
        kstr = 0;
      } else {
        kstr = (int)obj_Length;
      }
      b_bool = false;
      if (kstr == 9) {
        kstr = 0;
        do {
          exitg1 = 0;
          if (kstr < 9) {
            if (obj_Vector[kstr] != cv2[kstr]) {
              exitg1 = 1;
            } else {
              kstr++;
            }
          } else {
            b_bool = true;
            exitg1 = 1;
          }
        } while (exitg1 == 0);
      }
      if (b_bool) {
        bid = (double)b_i + 1.0;
        exitg2 = true;
      } else {
        b_i++;
      }
    }
  }
  return bid;
}

/*
 * Arguments    : f_robotics_manip_internal_Rigid *obj
 *                const char bodyname_data[]
 *                const int bodyname_size[2]
 * Return Type  : double
 */
double d_RigidBodyTree_findBodyIndexBy(f_robotics_manip_internal_Rigid *obj,
                                       const char bodyname_data[],
                                       const int bodyname_size[2])
{
  c_robotics_manip_internal_Rigid *b_obj;
  double bid;
  double obj_Length;
  int obj_Vector_size[2];
  int i;
  int loop_ub;
  char obj_Vector[200];
  char obj_Vector_data[200];
  bid = -1.0;
  obj_Length = obj->Base.NameInternal.Length;
  for (i = 0; i < 200; i++) {
    obj_Vector[i] = obj->Base.NameInternal.Vector[i];
  }
  if (obj_Length < 1.0) {
    loop_ub = 0;
  } else {
    loop_ub = (int)obj_Length;
  }
  obj_Vector_size[0] = 1;
  obj_Vector_size[1] = loop_ub;
  if (loop_ub - 1 >= 0) {
    memcpy(&obj_Vector_data[0], &obj_Vector[0],
           (unsigned int)loop_ub * sizeof(char));
  }
  if (b_strcmp(obj_Vector_data, obj_Vector_size, bodyname_data,
               bodyname_size)) {
    bid = 0.0;
  } else {
    double d;
    int b_i;
    bool exitg1;
    d = obj->NumBodies;
    b_i = 0;
    exitg1 = false;
    while ((!exitg1) && (b_i <= (int)d - 1)) {
      b_obj = obj->Bodies[b_i];
      obj_Length = b_obj->NameInternal.Length;
      for (i = 0; i < 200; i++) {
        obj_Vector[i] = b_obj->NameInternal.Vector[i];
      }
      if (obj_Length < 1.0) {
        loop_ub = 0;
      } else {
        loop_ub = (int)obj_Length;
      }
      obj_Vector_size[0] = 1;
      obj_Vector_size[1] = loop_ub;
      if (loop_ub - 1 >= 0) {
        memcpy(&obj_Vector_data[0], &obj_Vector[0],
               (unsigned int)loop_ub * sizeof(char));
      }
      if (b_strcmp(obj_Vector_data, obj_Vector_size, bodyname_data,
                   bodyname_size)) {
        bid = (double)b_i + 1.0;
        exitg1 = true;
      } else {
        b_i++;
      }
    }
  }
  return bid;
}

/*
 * Arguments    : f_robotics_manip_internal_Rigid *obj
 *                const char jointname_data[]
 *                const int jointname_size[2]
 * Return Type  : double
 */
double e_RigidBodyTree_findBodyIndexBy(f_robotics_manip_internal_Rigid *obj,
                                       const char jointname_data[],
                                       const int jointname_size[2])
{
  c_robotics_manip_internal_Rigid *b_obj;
  rigidBodyJoint *jnt;
  double bid;
  double d;
  int obj_Vector_size[2];
  int b_i;
  int i;
  char obj_Vector[200];
  char obj_Vector_data[200];
  bool exitg1;
  bid = -1.0;
  d = obj->NumBodies;
  i = 0;
  exitg1 = false;
  while ((!exitg1) && (i <= (int)d - 1)) {
    double obj_Length;
    int loop_ub;
    b_obj = obj->Bodies[i];
    jnt = b_obj->JointInternal;
    obj_Length = jnt->NameInternal.Length;
    for (b_i = 0; b_i < 200; b_i++) {
      obj_Vector[b_i] = jnt->NameInternal.Vector[b_i];
    }
    if (obj_Length < 1.0) {
      loop_ub = 0;
    } else {
      loop_ub = (int)obj_Length;
    }
    obj_Vector_size[0] = 1;
    obj_Vector_size[1] = loop_ub;
    if (loop_ub - 1 >= 0) {
      memcpy(&obj_Vector_data[0], &obj_Vector[0],
             (unsigned int)loop_ub * sizeof(char));
    }
    if (b_strcmp(obj_Vector_data, obj_Vector_size, jointname_data,
                 jointname_size)) {
      bid = (double)i + 1.0;
      exitg1 = true;
    } else {
      i++;
    }
  }
  return bid;
}

/*
 * File trailer for RigidBodyTree1.c
 *
 * [EOF]
 */
```

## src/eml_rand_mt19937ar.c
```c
/*
 * Sponsored License - for use in support of a program or activity
 * sponsored by MathWorks.  Not for government, commercial or other
 * non-sponsored organizational use.
 * File: eml_rand_mt19937ar.c
 *
 * MATLAB Coder version            : 25.2
 * C/C++ source code generated on  : 07-Mar-2026 20:10:01
 */

/* Include Files */
#include "eml_rand_mt19937ar.h"
#include "rt_nonfinite.h"

/* Function Definitions */
/*
 * Arguments    : unsigned int b_state[625]
 * Return Type  : void
 */
void eml_rand_mt19937ar(unsigned int b_state[625])
{
  int mti;
  unsigned int r;
  r = 5489U;
  b_state[0] = 5489U;
  for (mti = 0; mti < 623; mti++) {
    r = ((r ^ r >> 30U) * 1812433253U + (unsigned int)mti) + 1U;
    b_state[mti + 1] = r;
  }
  b_state[624] = 624U;
}

/*
 * File trailer for eml_rand_mt19937ar.c
 *
 * [EOF]
 */
```

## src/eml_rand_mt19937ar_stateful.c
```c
/*
 * Sponsored License - for use in support of a program or activity
 * sponsored by MathWorks.  Not for government, commercial or other
 * non-sponsored organizational use.
 * File: eml_rand_mt19937ar_stateful.c
 *
 * MATLAB Coder version            : 25.2
 * C/C++ source code generated on  : 07-Mar-2026 20:10:01
 */

/* Include Files */
#include "eml_rand_mt19937ar_stateful.h"
#include "eml_rand_mt19937ar.h"
#include "psudoinverse_function_data.h"
#include "rt_nonfinite.h"

/* Function Definitions */
/*
 * Arguments    : void
 * Return Type  : void
 */
void c_eml_rand_mt19937ar_stateful_i(void)
{
  eml_rand_mt19937ar(state);
}

/*
 * File trailer for eml_rand_mt19937ar_stateful.c
 *
 * [EOF]
 */
```

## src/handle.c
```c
/*
 * Sponsored License - for use in support of a program or activity
 * sponsored by MathWorks.  Not for government, commercial or other
 * non-sponsored organizational use.
 * File: handle.c
 *
 * MATLAB Coder version            : 25.2
 * C/C++ source code generated on  : 07-Mar-2026 20:10:01
 */

/* Include Files */
#include "handle.h"
#include "psudoinverse_function_types.h"
#include "rt_nonfinite.h"
#include "collisioncodegen_api.hpp"

/* Function Definitions */
/*
 * Arguments    : d_robotics_manip_internal_Colli *obj
 * Return Type  : void
 */
void handle_matlabCodegenDestructor(d_robotics_manip_internal_Colli *obj)
{
  c_robotics_manip_internal_Colli b_obj;
  int b_i;
  if (!obj->matlabCodegenIsDeleted) {
    double d;
    int i;
    obj->matlabCodegenIsDeleted = true;
    d = obj->Size;
    i = (int)d;
    for (b_i = 0; b_i < i; b_i++) {
      b_obj = obj->CollisionGeometries->data[b_i];
      collisioncodegen_destructGeometry(&b_obj.CollisionPrimitive);
      obj->CollisionGeometries->data[b_i] = b_obj;
    }
  }
}

/*
 * File trailer for handle.c
 *
 * [EOF]
 */
```

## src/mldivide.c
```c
/*
 * Sponsored License - for use in support of a program or activity
 * sponsored by MathWorks.  Not for government, commercial or other
 * non-sponsored organizational use.
 * File: mldivide.c
 *
 * MATLAB Coder version            : 25.2
 * C/C++ source code generated on  : 07-Mar-2026 20:10:01
 */

/* Include Files */
#include "mldivide.h"
#include "rt_nonfinite.h"
#include <math.h>
#include <string.h>

/* Function Definitions */
/*
 * Arguments    : const double A[9]
 *                const double B[3]
 *                double Y[3]
 * Return Type  : void
 */
void mldivide(const double A[9], const double B[3], double Y[3])
{
  double b_A[9];
  double a21;
  double maxval;
  int r1;
  int r2;
  int r3;
  memcpy(&b_A[0], &A[0], 9U * sizeof(double));
  r1 = 0;
  r2 = 1;
  r3 = 2;
  maxval = fabs(A[0]);
  a21 = fabs(A[1]);
  if (a21 > maxval) {
    maxval = a21;
    r1 = 1;
    r2 = 0;
  }
  if (fabs(A[2]) > maxval) {
    r1 = 2;
    r2 = 1;
    r3 = 0;
  }
  b_A[r2] = A[r2] / A[r1];
  b_A[r3] /= b_A[r1];
  b_A[r2 + 3] -= b_A[r2] * b_A[r1 + 3];
  b_A[r3 + 3] -= b_A[r3] * b_A[r1 + 3];
  b_A[r2 + 6] -= b_A[r2] * b_A[r1 + 6];
  b_A[r3 + 6] -= b_A[r3] * b_A[r1 + 6];
  if (fabs(b_A[r3 + 3]) > fabs(b_A[r2 + 3])) {
    int rtemp;
    rtemp = r2;
    r2 = r3;
    r3 = rtemp;
  }
  b_A[r3 + 3] /= b_A[r2 + 3];
  b_A[r3 + 6] -= b_A[r3 + 3] * b_A[r2 + 6];
  Y[1] = B[r2] - B[r1] * b_A[r2];
  Y[2] = (B[r3] - B[r1] * b_A[r3]) - Y[1] * b_A[r3 + 3];
  Y[2] /= b_A[r3 + 6];
  Y[0] = B[r1] - Y[2] * b_A[r1 + 6];
  Y[1] -= Y[2] * b_A[r2 + 6];
  Y[1] /= b_A[r2 + 3];
  Y[0] -= Y[1] * b_A[r1 + 3];
  Y[0] /= b_A[r1];
}

/*
 * File trailer for mldivide.c
 *
 * [EOF]
 */
```

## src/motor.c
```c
#include <stdio.h>
#include <zephyr/kernel.h>
#include <zephyr/drivers/gpio.h>
#include "motor.h"
const uint8_t sleep_time=100;

int step_motion(const struct stepper_motor *motor , int dir , int pos){
  if(dir==1){
    printk("Clockwise motion");
    gpio_pin_set_dt(&(motor->direction),1);
    pos+=1;
  }else if(dir==0){
    printk("Anticlockwise motion");
    gpio_pin_set_dt(&(motor->direction),0);
    pos-=1;
  }else {
    return pos;
  }
  gpio_pin_set_dt(&(motor->step),1);
  k_usleep(10);
  gpio_pin_set_dt(&(motor->step),0);
  k_usleep(10);
  /*
  int pulses=pos%4;
  if(pulses==0){
    gpio_pin_set_dt(&(motor->step),0);
  }else if(pulses==1){
    gpio_pin_set_dt(&(motor->step),1);
  }else if(pulses==2){
    gpio_pin_set_dt(&(motor->step),1);
  }else if(pulses==3){
    gpio_pin_set_dt(&(motor->step),0);
  }
  */
  return pos;


}
```

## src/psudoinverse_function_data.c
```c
/*
 * Sponsored License - for use in support of a program or activity
 * sponsored by MathWorks.  Not for government, commercial or other
 * non-sponsored organizational use.
 * File: psudoinverse_function_data.c
 *
 * MATLAB Coder version            : 25.2
 * C/C++ source code generated on  : 07-Mar-2026 20:10:01
 */

/* Include Files */
#include "psudoinverse_function_data.h"
#include "rt_nonfinite.h"

/* Variable Definitions */
unsigned int state[625];

const char cv[10] = {'d', 'u', 'm', 'm', 'y', 'b', 'o', 'd', 'y', '1'};

const signed char iv[16] = {1, 0, 0, 0, 0, 1, 0, 0, 0, 0, 1, 0, 0, 0, 0, 1};

const char cv1[9] = {'p', 'r', 'i', 's', 'm', 'a', 't', 'i', 'c'};

const char cv2[9] = {'b', 'a', 's', 'e', '_', 'l', 'i', 'n', 'k'};

const unsigned char uv[9] = {98U, 97U, 115U, 101U, 95U, 108U, 105U, 110U, 107U};

bool isInitialized_psudoinverse_function = false;

/*
 * File trailer for psudoinverse_function_data.c
 *
 * [EOF]
 */
```
